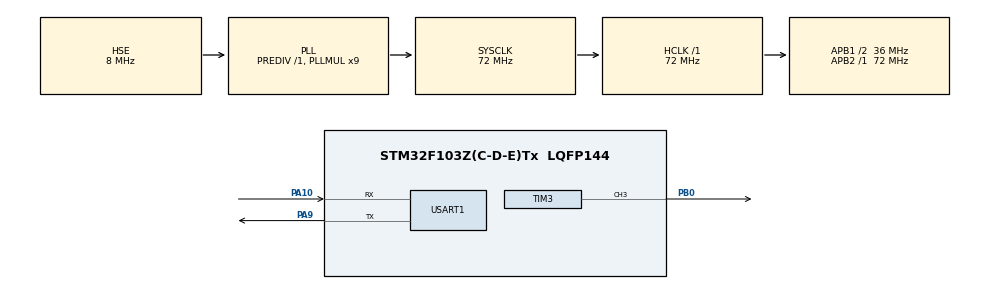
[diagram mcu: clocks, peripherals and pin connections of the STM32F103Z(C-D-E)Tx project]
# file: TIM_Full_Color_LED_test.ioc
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Dma.Request0=TIM3_CH3
Dma.TIM3_CH3.0.Direction=DMA_MEMORY_TO_PERIPH
Dma.TIM3_CH3.0.Instance=DMA1_Channel2
Dma.TIM3_CH3.0.MemDataAlignment=DMA_MDATAALIGN_HALFWORD
Dma.TIM3_CH3.0.MemInc=DMA_MINC_ENABLE
Dma.TIM3_CH3.0.Mode=DMA_NORMAL
Dma.TIM3_CH3.0.PeriphDataAlignment=DMA_PDATAALIGN_HALFWORD
Dma.TIM3_CH3.0.PeriphInc=DMA_PINC_DISABLE
Dma.TIM3_CH3.0.Priority=DMA_PRIORITY_LOW
Mcu.Family=STM32F1
Mcu.Name=STM32F103Z(C-D-E)Tx
Mcu.Package=LQFP144
NVIC.DMA1_Channel2_IRQn=true\:0\:0\:false\:false\:true\:false\:true\:true
NVIC.PriorityGroup=NVIC_PRIORITYGROUP_4
OSC_IN.Mode=HSE-External-Oscillator
OSC_IN.Signal=RCC_OSC_IN
OSC_OUT.Mode=HSE-External-Oscillator
OSC_OUT.Signal=RCC_OSC_OUT
PA10.Mode=Asynchronous
PA10.Signal=USART1_RX
PA13.Mode=Serial_Wire
PA13.Signal=SYS_JTMS-SWDIO
PA14.Mode=Serial_Wire
PA14.Signal=SYS_JTCK-SWCLK
PA9.Mode=Asynchronous
PA9.Signal=USART1_TX
PB0.Signal=S_TIM3_CH3
ProjectManager.HeapSize=0x200
ProjectManager.StackSize=0x400
ProjectManager.TargetToolchain=MDK-ARM V5.32
RCC.AHBFreq_Value=72000000
RCC.APB1CLKDivider=RCC_HCLK_DIV2
RCC.APB1Freq_Value=36000000
RCC.APB1TimFreq_Value=72000000
RCC.APB2Freq_Value=72000000
RCC.APB2TimFreq_Value=72000000
RCC.HCLKFreq_Value=72000000
RCC.PLLMUL=RCC_PLL_MUL9
RCC.PLLSourceVirtual=RCC_PLLSOURCE_HSE
RCC.SYSCLKFreq_VALUE=72000000
RCC.SYSCLKSource=RCC_SYSCLKSOURCE_PLLCLK
RCC.USBFreq_Value=72000000
SH.S_TIM3_CH3.0=TIM3_CH3,PWM Generation3 CH3
TIM3.Channel-PWM\ Generation3\ CH3=TIM_CHANNEL_3
TIM3.Period=63
USART1.Parity=PARITY_ODD
USART1.VirtualMode=VM_ASYNC
USART1.WordLength=WORDLENGTH_9B
board=custom

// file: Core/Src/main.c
/* USER CODE BEGIN Header */
/**
  ******************************************************************************
  * @file           : main.c
  * @brief          : Main program body
  ******************************************************************************
  * @attention
  *
  * Copyright (c) 2026 STMicroelectronics.
  * All rights reserved.
  *
  * This software is licensed under terms that can be found in the LICENSE file
  * in the root directory of this software component.
  * If no LICENSE file comes with this software, it is provided AS-IS.
  *
  ******************************************************************************
  */
/* USER CODE END Header */
#include "main.h"

/* USER CODE BEGIN Includes */
#include <stdio.h>
#include <stdlib.h>
#include "BSP_WS2812B.h"

/* USER CODE END Includes */

TIM_HandleTypeDef htim3;
DMA_HandleTypeDef hdma_tim3_ch3;

UART_HandleTypeDef huart1;

void SystemClock_Config(void);
static void MX_GPIO_Init(void);
static void MX_DMA_Init(void);
static void MX_TIM3_Init(void);
static void MX_USART1_UART_Init(void);

int main(void)
{

  /* MCU Configuration--------------------------------------------------------*/

  /* Reset of all peripherals, Initializes the Flash interface and the Systick. */
  HAL_Init();

  /* Configure the system clock */
  SystemClock_Config();

  /* Initialize all configured peripherals */
  MX_GPIO_Init();
  MX_DMA_Init();
  MX_TIM3_Init();
  MX_USART1_UART_Init();
  /* USER CODE BEGIN 2 */
  BSP_WS2812BInit(&htim3);
  BSP_WS2812BResetColor();
  srand((unsigned int)HAL_GetTick());
  int led_index = 0;
  /* USER CODE END 2 */

  /* Infinite loop */
  /* USER CODE BEGIN WHILE */
  while (1)
  {
    // 0. 重置
    BSP_WS2812BResetColor();

    // 1. 只点亮一颗灯，并按行依次移动
    int row = led_index / 3;
    int column = led_index % 3;
    rgb_t rgb1 = {rand() % 256, rand() % 256, rand() % 256};
    BSP_WS2812BSetColor(row, column, rgb1);

    // 2. 转化
    BSP_ConvertRGB2Pulse();

    // 3. 刷新
    BSP_WS2812BRefresh();

    // 4. 等待完成
    BSP_WaitDMADone();

    led_index = (led_index + 1) % 9;
    HAL_Delay(100);
    /* USER CODE END WHILE */

  }
}

void SystemClock_Config(void)
{
  RCC_OscInitTypeDef RCC_OscInitStruct = {0};
  RCC_ClkInitTypeDef RCC_ClkInitStruct = {0};

  /** Initializes the RCC Oscillators according to the specified parameters
  * in the RCC_OscInitTypeDef structure.
  */
  RCC_OscInitStruct.OscillatorType = RCC_OSCILLATORTYPE_HSE;
  RCC_OscInitStruct.HSEState = RCC_HSE_ON;
  RCC_OscInitStruct.HSEPredivValue = RCC_HSE_PREDIV_DIV1;
  RCC_OscInitStruct.HSIState = RCC_HSI_ON;
  RCC_OscInitStruct.PLL.PLLState = RCC_PLL_ON;
  RCC_OscInitStruct.PLL.PLLSource = RCC_PLLSOURCE_HSE;
  RCC_OscInitStruct.PLL.PLLMUL = RCC_PLL_MUL9;
  if (HAL_RCC_OscConfig(&RCC_OscInitStruct) != HAL_OK)
  {
    Error_Handler();
  }

  /** Initializes the CPU, AHB and APB buses clocks
  */
  RCC_ClkInitStruct.ClockType = RCC_CLOCKTYPE_HCLK|RCC_CLOCKTYPE_SYSCLK
                              |RCC_CLOCKTYPE_PCLK1|RCC_CLOCKTYPE_PCLK2;
  RCC_ClkInitStruct.SYSCLKSource = RCC_SYSCLKSOURCE_PLLCLK;
  RCC_ClkInitStruct.AHBCLKDivider = RCC_SYSCLK_DIV1;
  RCC_ClkInitStruct.APB1CLKDivider = RCC_HCLK_DIV2;
  RCC_ClkInitStruct.APB2CLKDivider = RCC_HCLK_DIV1;

  if (HAL_RCC_ClockConfig(&RCC_ClkInitStruct, FLASH_LATENCY_2) != HAL_OK)
  {
    Error_Handler();
  }
}

static void MX_TIM3_Init(void)
{

  TIM_MasterConfigTypeDef sMasterConfig = {0};
  TIM_OC_InitTypeDef sConfigOC = {0};

  htim3.Instance = TIM3;
  htim3.Init.Prescaler = 0;
  htim3.Init.CounterMode = TIM_COUNTERMODE_UP;
  htim3.Init.Period = 63;
  htim3.Init.ClockDivision = TIM_CLOCKDIVISION_DIV1;
  htim3.Init.AutoReloadPreload = TIM_AUTORELOAD_PRELOAD_DISABLE;
  if (HAL_TIM_PWM_Init(&htim3) != HAL_OK)
  {
    Error_Handler();
  }
  sMasterConfig.MasterOutputTrigger = TIM_TRGO_RESET;
  sMasterConfig.MasterSlaveMode = TIM_MASTERSLAVEMODE_DISABLE;
  if (HAL_TIMEx_MasterConfigSynchronization(&htim3, &sMasterConfig) != HAL_OK)
  {
    Error_Handler();
  }
  sConfigOC.OCMode = TIM_OCMODE_PWM1;
  sConfigOC.Pulse = 0;
  sConfigOC.OCPolarity = TIM_OCPOLARITY_HIGH;
  sConfigOC.OCFastMode = TIM_OCFAST_DISABLE;
  if (HAL_TIM_PWM_ConfigChannel(&htim3, &sConfigOC, TIM_CHANNEL_3) != HAL_OK)
  {
    Error_Handler();
  }
  HAL_TIM_MspPostInit(&htim3);

}

static void MX_USART1_UART_Init(void)
{

  huart1.Instance = USART1;
  huart1.Init.BaudRate = 115200;
  huart1.Init.WordLength = UART_WORDLENGTH_9B;
  huart1.Init.StopBits = UART_STOPBITS_1;
  huart1.Init.Parity = UART_PARITY_ODD;
  huart1.Init.Mode = UART_MODE_TX_RX;
  huart1.Init.HwFlowCtl = UART_HWCONTROL_NONE;
  huart1.Init.OverSampling = UART_OVERSAMPLING_16;
  if (HAL_UART_Init(&huart1) != HAL_OK)
  {
    Error_Handler();
  }

}

static void MX_DMA_Init(void)
{

  /* DMA controller clock enable */
  __HAL_RCC_DMA1_CLK_ENABLE();

  /* DMA interrupt init */
  /* DMA1_Channel2_IRQn interrupt configuration */
  HAL_NVIC_SetPriority(DMA1_Channel2_IRQn, 0, 0);
  HAL_NVIC_EnableIRQ(DMA1_Channel2_IRQn);

}

static void MX_GPIO_Init(void)
{

  /* GPIO Ports Clock Enable */
  __HAL_RCC_GPIOB_CLK_ENABLE();
  __HAL_RCC_GPIOA_CLK_ENABLE();

}

/* USER CODE BEGIN 4 */

// DMA 完成
void HAL_TIM_PWM_PulseFinishedCallback(TIM_HandleTypeDef *htim)
{
  if (htim == &htim3)
  {
    BSP_DMAPulseCplt();
  }
}

/* USER CODE END 4 */

void Error_Handler(void)
{
  __disable_irq();
  while (1)
  {
  }
}
